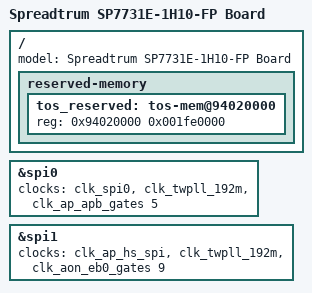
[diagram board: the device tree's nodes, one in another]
/*
 * Spreadtrum SP7731E 1H10 WITH FINGERPRINT board DTS file
 *
 * Copyright (C) 2016-2017, Spreadtrum Communications Inc.
 *
 * This file is licensed under a dual GPLv2 or X11 license.
 */
#include "sp7731e-1h10-native.dts"

/ {
	model = "Spreadtrum SP7731E-1H10-FP Board";
	reserved-memory {
		tos_reserved: tos-mem@94020000{
			reg = <0x94020000 0x001fe0000>;
		};
	};

};

&spi0 {
		clocks = <&clk_spi0>, <&clk_twpll_192m>,
				<&clk_ap_apb_gates 5>;
};

&spi1 {
		clocks = <&clk_ap_hs_spi>, <&clk_twpll_192m>,
				<&clk_aon_eb0_gates 9>;
		status = "okay";
};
